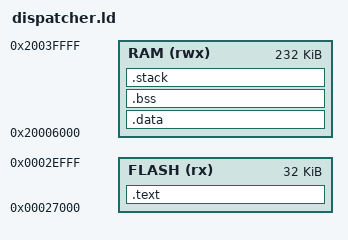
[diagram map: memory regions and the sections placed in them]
/* src/dispatcher/dispatcher.ld */

ENTRY(Reset_Handler)

MEMORY
{
  FLASH (rx) : ORIGIN = 0x27000, LENGTH = 0x8000
  RAM (rwx) :  ORIGIN = 0x20006000, LENGTH = 0x20040000 - 0x20006000
}

SECTIONS
{
  .text : {
    KEEP(*(.vectors))
    KEEP(*(.isr_vector))
    *(.text*)
    *(.rodata*)
  } > FLASH

  .data : AT (ADDR(.text) + SIZEOF(.text)) {
    __data_start__ = .;
    *(.data*)
    __data_end__ = .;
  } > RAM

  .bss : {
    __bss_start__ = .;
    *(.bss*)
    *(COMMON)
    __bss_end__ = .;
  } > RAM

  .stack (COPY) :
  {
    __stack_top__ = ORIGIN(RAM) + LENGTH(RAM);
    __stack_limit__ = __stack_top__ - 0x1000;
  } > RAM
}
